# ATtiny48 device description
Architecture: AVR8; Family: tinyAVR
Registers are 8-bit, access not given, no defined reset value unless marked. A register's access mark holds for its fields unless they carry their own. Offsets are from the block's base; [hi:lo] are bit positions; {n}, {i} and the like mark numbered series; 'fields as' and 'values as' point back to an identical list.

## TWI — Two Wire Serial Interface
Instances: TWI 0x00
0xB8 TWBR — TWI Bit Rate register
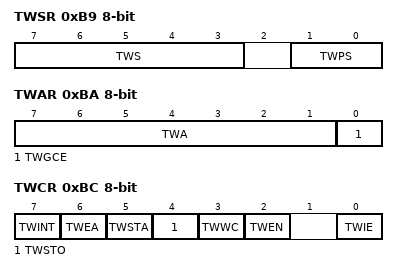
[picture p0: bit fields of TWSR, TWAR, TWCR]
0xB9 TWSR — TWI Status Register
  [7:3] TWS (bit 3 of the value upward) — TWI Status
  [1:0] TWPS — TWI Prescaler
    0=1; 1=4; 2=16; 3=64
0xBA TWAR — TWI (Slave) Address register
  [7:1] TWA — TWI (Slave) Address register Bits
  [0] TWGCE — TWI General Call Recognition Enable Bit
0xBB TWDR — TWI Data register
0xBC TWCR — TWI Control Register
  [7] TWINT — TWI Interrupt Flag
  [6] TWEA — TWI Enable Acknowledge Bit
  [5] TWSTA — TWI Start Condition Bit
  [4] TWSTO — TWI Stop Condition Bit
  [3] TWWC — TWI Write Collision Flag
  [2] TWEN — TWI Enable Bit
  [0] TWIE — TWI Interrupt Enable
0xBD TWAMR — TWI (Slave) Address Mask Register
  [7:1] TWAM
0xBE TWHSR
  [0] TWHS

## ADC — Analog-to-Digital Converter
Instances: ADC 0x00
0x78 ADC 16-bit — ADC Data Register Bytes
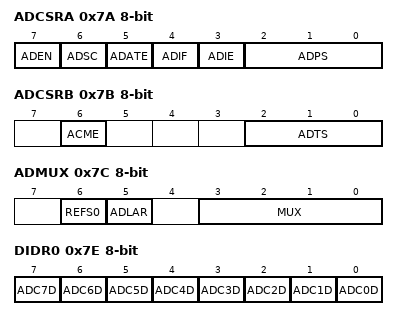
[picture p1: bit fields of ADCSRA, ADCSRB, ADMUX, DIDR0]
0x7A ADCSRA — The ADC Control and Status register A
  [7] ADEN — ADC Enable
  [6] ADSC — ADC Start Conversion
  [5] ADATE — ADC Auto Trigger Enable
  [4] ADIF — ADC Interrupt Flag
  [3] ADIE — ADC Interrupt Enable
  [2:0] ADPS — ADC Prescaler Select Bits
    0=2; 1=2; 2=4; 3=8; 4=16; 5=32; 6=64; 7=128
0x7B ADCSRB — The ADC Control and Status register B
  [6] ACME
  [2:0] ADTS — ADC Auto Trigger Source bits
    0=FREE_RUNNING_MODE; 1=ANALOG_COMPARATOR; 2=EXTERNAL_INTERRUPT_REQUEST_0; 3=TIMER_COUNTER0_COMPARE_MATCH_A; 4=TIMER_COUNTER0_OVERFLOW; 5=TIMER_COUNTER1_COMPARE_MATCH_B; 6=TIMER_COUNTER1_OVERFLOW; 7=TIMER_COUNTER1_CAPTURE_EVENT
0x7C ADMUX — The ADC multiplexer Selection Register
  [6] REFS0 — Reference Selection Bit 0
    0=INTERNAL_1_1V_VOLTAGE_REFERENCE; 1=AVCC_REFERENCE
  [5] ADLAR — Left Adjust Result
  [3:0] MUX — Analog Channel and Gain Selection Bits
0x7E DIDR0 — Digital Input Disable Register 0
  [n] ADC{n}D (n=0..7)
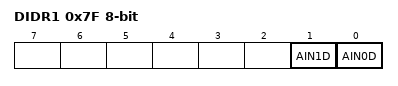
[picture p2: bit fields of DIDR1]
0x7F DIDR1 — Digital Input Disable Register 1
  [1] AIN1D, [0] AIN0D

## EXINT — External Interrupts
Instances: EXINT 0x00
0x3B PCIFR — Pin Change Interrupt Flag Register
  [3:0] PCIF — Pin Change Interrupt Flags
0x3C EIFR — External Interrupt Flag Register
  [1:0] INTF — External Interrupt Flags
0x3D EIMSK — External Interrupt Mask Register
  [1:0] INT — External Interrupt Request 1 Enable
0x68 PCICR
  [3:0] PCIE
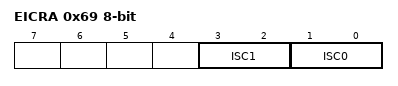
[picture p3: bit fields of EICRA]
0x69 EICRA — External Interrupt Control Register
  [3:2] ISC1 — External Interrupt Sense Control 1 Bits
    0=LOW_LEVEL_OF_INTX; 1=ANY_LOGICAL_CHANGE_IN_INTX; 2=FALLING_EDGE_OF_INTX; 3=RISING_EDGE_OF_INTX
  [1:0] ISC0 — External Interrupt Sense Control 0 Bits
    values as ISC1
0x6A PCMSK3 — Pin Change Mask Register 3
  [3:0] PCINT (bit 24 of the value upward) — Pin Change Enable Masks
0x6B PCMSK0 — Pin Change Mask Register 0
  [7:0] PCINT — Pin Change Enable Masks
0x6C PCMSK1 — Pin Change Mask Register 1
  [7:0] PCINT (bit 8 of the value upward) — Pin Change Enable Masks
0x6D PCMSK2 — Pin Change Mask Register 2
  [7:0] PCINT (bit 16 of the value upward) — Pin Change Enable Masks

## TC0 (TC8 module) — Timer/Counter, 8-bit
Instances: TC0 0x00
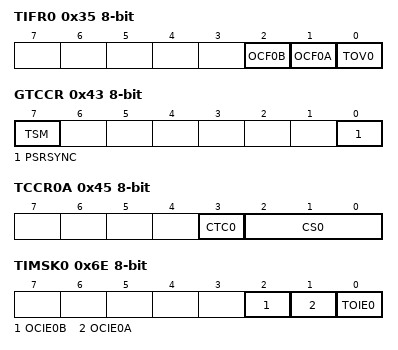
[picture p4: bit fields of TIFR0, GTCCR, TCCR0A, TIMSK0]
0x35 TIFR0 — Timer/Counter0 Interrupt Flag register
  [2] OCF0B — Timer/Counter0 Output Compare Flag 0B
  [1] OCF0A — Timer/Counter0 Output Compare Flag 0A
  [0] TOV0 — Timer/Counter0 Overflow Flag
0x43 GTCCR — General Timer/Counter Control Register
  [7] TSM — Timer/Counter Synchronization Mode
  [0] PSRSYNC — Prescaler Reset Timer/Counter1 and Timer/Counter0
0x45 TCCR0A — Timer/Counter Control Register A
  [3] CTC0 — Clear Timer on Compare Match
  [2:0] CS0 — Clock Select
    0=NO_CLOCK_SOURCE_STOPPED; 1=RUNNING_NO_PRESCALING; 2=RUNNING_CLK_8; 3=RUNNING_CLK_64; 4=RUNNING_CLK_256; 5=RUNNING_CLK_1024; 6=RUNNING_EXTCLK_TN_FALLING_EDGE; 7=RUNNING_EXTCLK_TN_RISING_EDGE
0x46 TCNT0 — Timer/Counter0
0x47 OCR0A — Timer/Counter0 Output Compare Register
0x48 OCR0B — Timer/Counter0 Output Compare Register
0x6E TIMSK0 — Timer/Counter0 Interrupt Mask Register
  [2] OCIE0B — Timer/Counter0 Output Compare Match B Interrupt Enable
  [1] OCIE0A — Timer/Counter0 Output Compare Match A Interrupt Enable
  [0] TOIE0 — Timer/Counter0 Overflow Interrupt Enable

## EEPROM
Instances: EEPROM 0x00
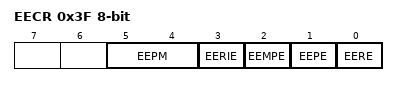
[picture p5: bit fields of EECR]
0x3F EECR — EEPROM Control Register
  [5:4] EEPM — EEPROM Programming Mode Bits
    0=ERASE_AND_WRITE_IN_ONE_OPERATION; 1=ERASE_ONLY; 2=WRITE_ONLY
  [3] EERIE — EEPROM Ready Interrupt Enable
  [2] EEMPE — EEPROM Master Write Enable
  [1] EEPE — EEPROM Write Enable
  [0] EERE — EEPROM Read Enable
0x40 EEDR — EEPROM Data Register
0x41 EEARL bits used 5:0 — EEPROM Address Register Low Byte
